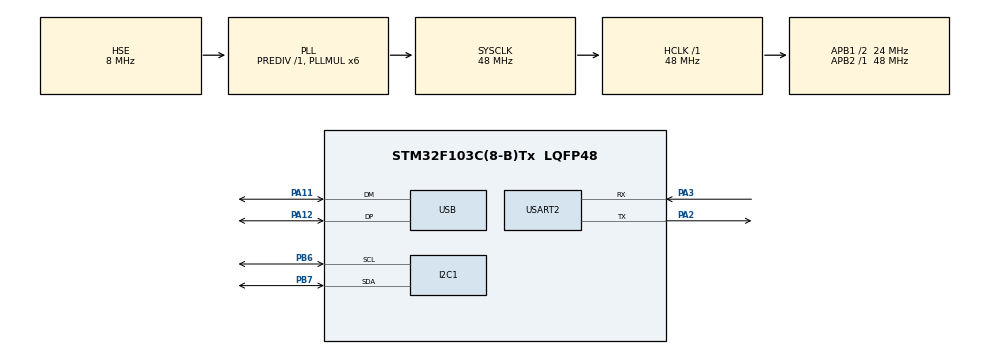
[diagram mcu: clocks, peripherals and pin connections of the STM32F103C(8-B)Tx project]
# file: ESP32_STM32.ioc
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Mcu.Family=STM32F1
Mcu.Name=STM32F103C(8-B)Tx
Mcu.Package=LQFP48
NVIC.PriorityGroup=NVIC_PRIORITYGROUP_4
NVIC.USB_LP_CAN1_RX0_IRQn=true\:0\:0\:false\:false\:true\:false\:true\:true
PA11.Mode=Device
PA11.Signal=USB_DM
PA12.Mode=Device
PA12.Signal=USB_DP
PA2.Mode=Asynchronous
PA2.Signal=USART2_TX
PA3.Mode=Asynchronous
PA3.Signal=USART2_RX
PB6.Mode=I2C
PB6.Signal=I2C1_SCL
PB7.Mode=I2C
PB7.Signal=I2C1_SDA
PD0-OSC_IN.Mode=HSE-External-Oscillator
PD0-OSC_IN.Signal=RCC_OSC_IN
PD1-OSC_OUT.Mode=HSE-External-Oscillator
PD1-OSC_OUT.Signal=RCC_OSC_OUT
ProjectManager.HeapSize=0x200
ProjectManager.StackSize=0x400
ProjectManager.TargetToolchain=MDK-ARM V5.32
RCC.AHBFreq_Value=48000000
RCC.APB1CLKDivider=RCC_HCLK_DIV2
RCC.APB1Freq_Value=24000000
RCC.APB1TimFreq_Value=48000000
RCC.APB2Freq_Value=48000000
RCC.APB2TimFreq_Value=48000000
RCC.HCLKFreq_Value=48000000
RCC.PLLMUL=RCC_PLL_MUL6
RCC.SYSCLKFreq_VALUE=48000000
RCC.SYSCLKSource=RCC_SYSCLKSOURCE_PLLCLK
RCC.USBFreq_Value=48000000
USART2.VirtualMode=VM_ASYNC
USB_DEVICE.CLASS_NAME_FS=CDC
USB_DEVICE.VirtualMode=Cdc
USB_DEVICE.VirtualModeFS=Cdc_FS
VP_SYS_VS_ND.Mode=No_Debug
VP_USB_DEVICE_VS_USB_DEVICE_CDC_FS.Mode=CDC_FS
board=custom

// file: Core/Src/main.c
/* USER CODE BEGIN Header */
/**
  ******************************************************************************
  * @file           : main.c
  * @brief          : Main program body
  ******************************************************************************
  * @attention
  *
  * Copyright (c) 2024 STMicroelectronics.
  * All rights reserved.
  *
  * This software is licensed under terms that can be found in the LICENSE file
  * in the root directory of this software component.
  * If no LICENSE file comes with this software, it is provided AS-IS.
  *
  ******************************************************************************
  */
/* USER CODE END Header */
#include "main.h"
#include "usb_device.h"
#include "usbd_cdc_if.h"
#include "stm32f1xx.h"

I2C_HandleTypeDef hi2c1;

UART_HandleTypeDef huart2;

/* USER CODE BEGIN PV */
uint8_t enviar[2] = {0x01,0x1D};
uint8_t recibir[6];
int16_t XaxisW,YaxisW,ZaxisW;
int AsMag;

/* USER CODE END PV */

void SystemClock_Config(void);
static void MX_GPIO_Init(void);
static void MX_USART2_UART_Init(void);
static void MX_I2C1_Init(void);

int main(void)
{

  /* MCU Configuration--------------------------------------------------------*/

  /* Reset of all peripherals, Initializes the Flash interface and the Systick. */
  HAL_Init();

  /* Configure the system clock */
  SystemClock_Config();

  /* Initialize all configured peripherals */
  MX_GPIO_Init();
  MX_USART2_UART_Init();
  MX_USB_DEVICE_Init();
  MX_I2C1_Init();

  /* Infinite loop */
  /* USER CODE BEGIN WHILE */

	HAL_I2C_Mem_Write(&hi2c1, 0x1A, 0x0B, 1, &enviar[0], 1, 100);
	HAL_I2C_Mem_Write(&hi2c1, 0x1A, 0x09, 1, &enviar[1], 1, 100);

	int Xgap = -400;
	int Ygap = -520;
	int Zgap = 0;

  while (1)
  {
    /* USER CODE END WHILE */
		/* USER CODE END WHILE */
		 /* USER CODE END WHILE */
		/* USER CODE END WHILE */
		HAL_I2C_Mem_Read(&hi2c1, 0x1A, 0x06, 1, recibir, 1, 100);
		uint8_t mensaje[18] = " 0000, 0000, 0000 ";
		mensaje[17] = 10;
		//if(recibir[0]&0x01){
				HAL_I2C_Mem_Read(&hi2c1, 0x1A, 0x00, 1, recibir, 6, 100);
				XaxisW = (recibir[1]<<8) | recibir[0];
				YaxisW = (recibir[3]<<8) | recibir[2];
				ZaxisW = (recibir[5]<<8) | recibir[4];
		//}
		int Xaxis = XaxisW - Xgap;
		int Yaxis = YaxisW - Ygap;
		int Zaxis = ZaxisW - Zgap;

		if(Xaxis >= 0){
			mensaje[0] = 32;
		} else {
			mensaje[0] = 45;
		}

		if(abs(Xaxis) > 1000){
			mensaje[1] = abs(Xaxis)/1000 + 48;
			Xaxis = abs(Xaxis)%1000;
		} else{
					mensaje[1] = 48;
			}
		if(abs(Xaxis) > 100){
			mensaje[2] = abs(Xaxis)/100 + 48;
			Xaxis = abs(Xaxis)%100;
		} else{
					mensaje[2] = 48;
			}
		if(abs(Xaxis) > 10){
			mensaje[3] = abs(Xaxis)/10 + 48;
			Xaxis = abs(Xaxis)%10;
		} else{
					mensaje[3] = 48;
			}
		mensaje[4] = abs(Xaxis) + 48;

		if (Xaxis + 48 >= 58){
				mensaje[4] = 48; // Asegurar un valor válido si Zaxis es menor a 10
		}

		if(Yaxis >= 0){
			mensaje[6] = 32;
		} else {
			mensaje[6] = 45;
		}

		if(abs(Yaxis) > 1000){
			mensaje[7] = abs(Yaxis)/1000 + 48;
			Yaxis = abs(Yaxis)%1000;
			} else{
					mensaje[7] = 48;
			}
		if(abs(Yaxis) > 100){
			mensaje[8] = abs(Yaxis)/100 + 48;
			Yaxis = abs(Yaxis)%100;
			} else{
					mensaje[8] = 48;
			}
		if(abs(Yaxis) > 10){
			mensaje[9] = abs(Yaxis)/10 + 48;
			Yaxis = abs(Yaxis)%10;
			} else{
				mensaje[9] = 48;
			}

	  mensaje[10] = abs(Yaxis) + 48;
			if (Yaxis + 48 >= 58){
				mensaje[10] = 48; // Asegurar un valor válido si Zaxis es menor a 10
			}

		if(Zaxis >= 0){
			mensaje[12] = 32;
		} else {
			mensaje[12] = 45;
		}

		if(abs(Zaxis) > 1000){
			mensaje[13] = abs(Zaxis)/1000 + 48;
			Zaxis = abs(Zaxis)%1000;
			} else{
					mensaje[13] = 48;
			}
		if(abs(Zaxis) > 100){
			mensaje[14] = abs(Zaxis)/100 + 48;
			Zaxis = abs(Zaxis)%100;
			} else{
					mensaje[14] = 48;
			}
		if(abs(Zaxis) > 10){
			mensaje[15] = abs(Zaxis)/10 + 48;
			Zaxis = abs(Zaxis)%10;
			} else{
					mensaje[15] = 48;
			}

		mensaje[16] = abs(Zaxis) + 48;
			if (Zaxis + 48 >= 58){
					mensaje[16] = 48; // Asegurar un valor válido si Zaxis es menor a 10
			}
		CDC_Transmit_FS(mensaje,18);
		HAL_UART_Transmit(&huart2, mensaje, sizeof(mensaje), HAL_MAX_DELAY);
		HAL_Delay(100);

  }
}

void SystemClock_Config(void)
{
  RCC_OscInitTypeDef RCC_OscInitStruct = {0};
  RCC_ClkInitTypeDef RCC_ClkInitStruct = {0};
  RCC_PeriphCLKInitTypeDef PeriphClkInit = {0};

  /** Initializes the RCC Oscillators according to the specified parameters
  * in the RCC_OscInitTypeDef structure.
  */
  RCC_OscInitStruct.OscillatorType = RCC_OSCILLATORTYPE_HSE;
  RCC_OscInitStruct.HSEState = RCC_HSE_ON;
  RCC_OscInitStruct.HSEPredivValue = RCC_HSE_PREDIV_DIV1;
  RCC_OscInitStruct.HSIState = RCC_HSI_ON;
  RCC_OscInitStruct.PLL.PLLState = RCC_PLL_ON;
  RCC_OscInitStruct.PLL.PLLSource = RCC_PLLSOURCE_HSE;
  RCC_OscInitStruct.PLL.PLLMUL = RCC_PLL_MUL6;
  if (HAL_RCC_OscConfig(&RCC_OscInitStruct) != HAL_OK)
  {
    Error_Handler();
  }

  /** Initializes the CPU, AHB and APB buses clocks
  */
  RCC_ClkInitStruct.ClockType = RCC_CLOCKTYPE_HCLK|RCC_CLOCKTYPE_SYSCLK
                              |RCC_CLOCKTYPE_PCLK1|RCC_CLOCKTYPE_PCLK2;
  RCC_ClkInitStruct.SYSCLKSource = RCC_SYSCLKSOURCE_PLLCLK;
  RCC_ClkInitStruct.AHBCLKDivider = RCC_SYSCLK_DIV1;
  RCC_ClkInitStruct.APB1CLKDivider = RCC_HCLK_DIV2;
  RCC_ClkInitStruct.APB2CLKDivider = RCC_HCLK_DIV1;

  if (HAL_RCC_ClockConfig(&RCC_ClkInitStruct, FLASH_LATENCY_1) != HAL_OK)
  {
    Error_Handler();
  }
  PeriphClkInit.PeriphClockSelection = RCC_PERIPHCLK_USB;
  PeriphClkInit.UsbClockSelection = RCC_USBCLKSOURCE_PLL;
  if (HAL_RCCEx_PeriphCLKConfig(&PeriphClkInit) != HAL_OK)
  {
    Error_Handler();
  }
}

static void MX_I2C1_Init(void)
{

  hi2c1.Instance = I2C1;
  hi2c1.Init.ClockSpeed = 100000;
  hi2c1.Init.DutyCycle = I2C_DUTYCYCLE_2;
  hi2c1.Init.OwnAddress1 = 0;
  hi2c1.Init.AddressingMode = I2C_ADDRESSINGMODE_7BIT;
  hi2c1.Init.DualAddressMode = I2C_DUALADDRESS_DISABLE;
  hi2c1.Init.OwnAddress2 = 0;
  hi2c1.Init.GeneralCallMode = I2C_GENERALCALL_DISABLE;
  hi2c1.Init.NoStretchMode = I2C_NOSTRETCH_DISABLE;
  if (HAL_I2C_Init(&hi2c1) != HAL_OK)
  {
    Error_Handler();
  }

}

static void MX_USART2_UART_Init(void)
{

  huart2.Instance = USART2;
  huart2.Init.BaudRate = 115200;
  huart2.Init.WordLength = UART_WORDLENGTH_8B;
  huart2.Init.StopBits = UART_STOPBITS_1;
  huart2.Init.Parity = UART_PARITY_NONE;
  huart2.Init.Mode = UART_MODE_TX_RX;
  huart2.Init.HwFlowCtl = UART_HWCONTROL_NONE;
  huart2.Init.OverSampling = UART_OVERSAMPLING_16;
  if (HAL_UART_Init(&huart2) != HAL_OK)
  {
    Error_Handler();
  }

}

static void MX_GPIO_Init(void)
{

  /* GPIO Ports Clock Enable */
  __HAL_RCC_GPIOD_CLK_ENABLE();
  __HAL_RCC_GPIOA_CLK_ENABLE();
  __HAL_RCC_GPIOB_CLK_ENABLE();

}

void Error_Handler(void)
{
  __disable_irq();
  while (1)
  {
  }
}
